# PIC32CZ4010CA90144 register map
Vendor: Microchip Technology; Series: PIC32CZCA90; File version: 0
CPU: CM7 r1p1, selectable endian, MPU, FPU, 3 interrupt priority bits
Registers are 32-bit, read-write, reset 0x0 unless marked. A register's access mark holds for its fields unless they carry their own. Offsets are from the block's base; [hi:lo] are bit positions; {n}, {i} and the like mark numbered series; 'fields as' and 'values as' point back to an identical list.

## PRM — Boot ROM Controller
Base 0x44080000; register names take the prefix PRM_
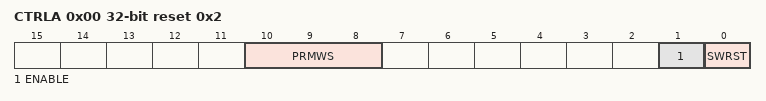
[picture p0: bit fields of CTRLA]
0x00 CTRLA reset 0x2 — CONTROL A REGISTER
  [10:8] PRMWS — ROM ACCESS TIME WAIT STATE
  [1] ENABLE — ENABLE BIT
  [0] SWRST — SOFTWARE RESET BIT

## PTC — Peripheral Touch Controller
Base 0x46828000; register names take the prefix PTC_

## RSTC — Reset Controller
Base 0x44030000; register names take the prefix RSTC_
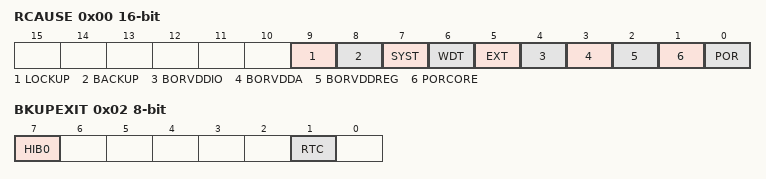
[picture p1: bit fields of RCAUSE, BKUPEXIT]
0x00 RCAUSE 16-bit ro — Reset Cause
  [9] LOCKUP — Lockup Reset
  [8] BACKUP — Backup Reset
  [7] SYST — System Reset Request
  [6] WDT — Watchdog Reset
  [5] EXT — External Reset
  [4] BORVDDIO — Brown Out VDDIO Detector Reset
  [3] BORVDDA — Brown Out VDDA Detector Reset
  [2] BORVDDREG — Brown Out VDDREG Detector Reset
  [1] PORCORE — Brown Out CORE Detector Reset
  [0] POR — Power On Reset
0x02 BKUPEXIT 8-bit ro — Backup Exit Source. Implemented only if RSTC_BACKUP_IMPLEMENTED=1
  [7] HIB0 — Hibernate
  [1] RTC — Real Timer Counter Interrupt
0x04 DBGCTRL — Debug Control
  [0] LCKUPDIS — Lockup Disable

## SysTick — System timer
Base 0xE000E010; register names take the prefix SysTick_
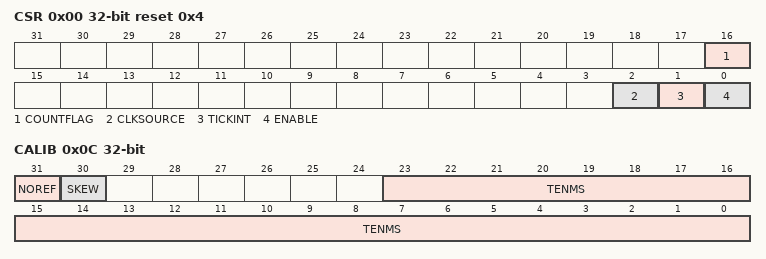
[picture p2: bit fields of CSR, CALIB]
0x00 CSR reset 0x4 — SysTick Control and Status Register
  [16] COUNTFLAG — Timer counted to 0 since last read of register
  [2] CLKSOURCE — Clock Source 0=external, 1=processor
    0=External clock; 1=Processor clock
  [1] TICKINT — SysTick Exception Request Enable
    0=Counting down to 0 does not assert the SysTick exception request; 1=Counting down to 0 asserts the SysTick exception request
  [0] ENABLE — SysTick Counter Enable
    0=Counter disabled; 1=Counter enabled
0x04 RVR — SysTick Reload Value Register
  [23:0] RELOAD — Value to load into the SysTick Current Value Register when the counter reaches 0
0x08 CVR — SysTick Current Value Register
  [23:0] CURRENT — Current value at the time the register is accessed
0x0C CALIB ro — SysTick Calibration Value Register
  [31] NOREF — No Separate Reference Clock
    0=The reference clock is provided; 1=The reference clock is not provided
  [30] SKEW — TENMS is rounded from non-integer ratio
    0=10ms calibration value is exact; 1=10ms calibration value is inexact, because of the clock frequency
  [23:0] TENMS — Reload value to use for 10ms timing

## TPI — Trace Port Interface Register
Base 0xE0040000; register names take the prefix TPI_
0x00 SSPSR ro — Supported Parallel Port Size Register
0x04 CSPSR — Current Parallel Port Size Register
0x10 ACPR — Asynchronous Clock Prescaler Register
  [12:0] PRESCALER
0xF0 SPPR — Selected Pin Protocol Register
  [1:0] TXMODE
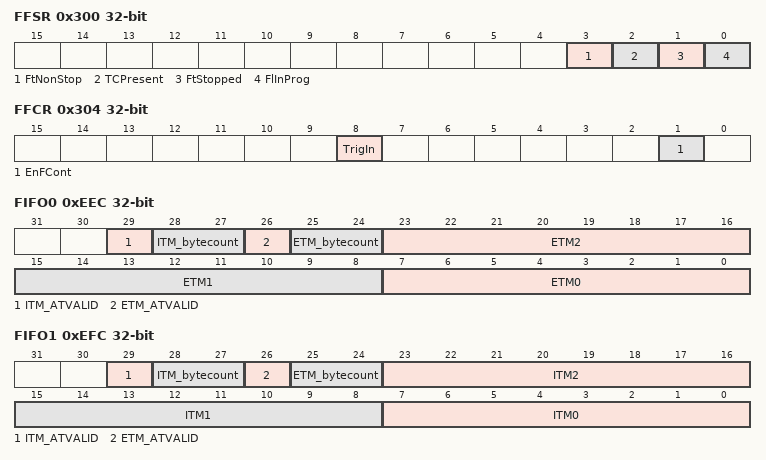
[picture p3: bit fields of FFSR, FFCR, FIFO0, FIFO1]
0x300 FFSR ro — Formatter and Flush Status Register
  [3] FtNonStop, [2] TCPresent, [1] FtStopped, [0] FlInProg
0x304 FFCR — Formatter and Flush Control Register
  [8] TrigIn, [1] EnFCont
0x308 FSCR ro — Formatter Synchronization Counter Register
0xEE8 TRIGGER ro
  [0] TRIGGER
0xEEC FIFO0 ro — Integration ETM Data
  [29] ITM_ATVALID, [28:27] ITM_bytecount, [26] ETM_ATVALID, [25:24] ETM_bytecount, [23:16] ETM2, [15:8] ETM1, [7:0] ETM0
0xEF0 ITATBCTR2 ro
  [0] ATREADY
0xEF8 ITATBCTR0 ro
  [0] ATREADY
0xEFC FIFO1 ro — Integration ITM Data
  [29] ITM_ATVALID, [28:27] ITM_bytecount, [26] ETM_ATVALID, [25:24] ETM_bytecount, [23:16] ITM2, [15:8] ITM1, [7:0] ITM0
0xF00 ITCTRL — Integration Mode Control
  [0] Mode
0xFA0 CLAIMSET — Claim tag set
0xFA4 CLAIMCLR — Claim tag clear
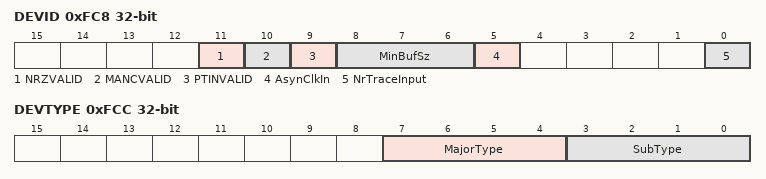
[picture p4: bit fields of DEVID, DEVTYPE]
0xFC8 DEVID ro — TPIU_DEVID
  [11] NRZVALID, [10] MANCVALID, [9] PTINVALID, [8:6] MinBufSz, [5] AsynClkIn, [0] NrTraceInput
0xFCC DEVTYPE ro — TPIU_DEVTYPE
  [7:4] MajorType, [3:0] SubType

## TRAM — TrustRAM
Base 0x44824000; register names take the prefix TRAM_
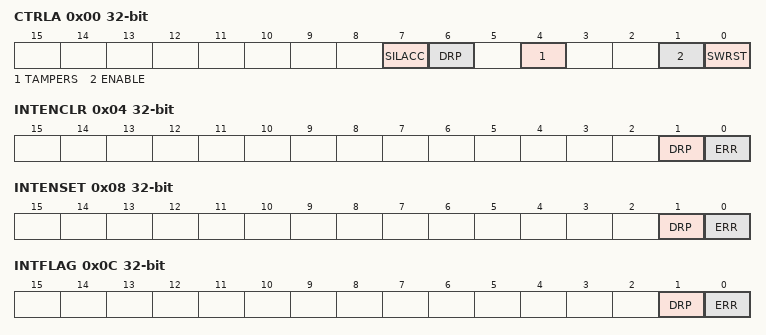
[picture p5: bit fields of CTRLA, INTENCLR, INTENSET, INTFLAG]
0x00 CTRLA — Control
  [7] SILACC — Silent Access
  [6] DRP — Data Remanence Prevention
  [4] TAMPERS — Tamper Erase
  [1] ENABLE
  [0] SWRST — Software Reset
0x04 INTENCLR — Interrupt Enable Clear
  [1] DRP — Data Remanence Prevention Ended Interrupt Enable
  [0] ERR — TrustRAM Readout Error Interrupt Enable
0x08 INTENSET — Interrupt Enable Set
  fields as INTENCLR
0x0C INTFLAG — Interrupt Flag Status and Clear
  [1] DRP — Data Remanence Prevention Ended
  [0] ERR — TrustRAM Readout Error
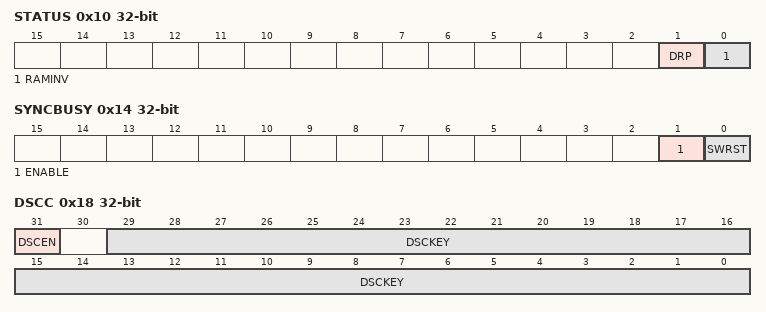
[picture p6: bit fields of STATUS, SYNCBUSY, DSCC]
0x10 STATUS ro
  [1] DRP — Data Remanence Prevention Ongoing
  [0] RAMINV — RAM Inversion Bit
0x14 SYNCBUSY ro — Synchronization Busy Status
  [1] ENABLE — Enable Busy
  [0] SWRST — Software Reset Busy
0x18 DSCC wo — Data Scramble Control
  [31] DSCEN — Data Scramble Enable
  [29:0] DSCKEY — Data Scramble Key
0x1C PERMW wo — Permutation Write
  [2:0] DATA — Permutation Scrambler Data Input
0x20 PERMR ro — Permutation Read
  [2:0] DATA — Permutation Scrambler Data Output
{0x1000+4i} RAM[{i}] (i=0..2047) — TrustRAM
  [31:0] DATA — Trust RAM Data

## TRNG — True Random Generator
Base 0x44870000; register names take the prefix TRNG_
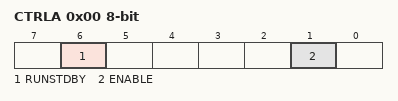
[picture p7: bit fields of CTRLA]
0x00 CTRLA 8-bit — Control A
  [6] RUNSTDBY — Run in Standby
  [1] ENABLE
0x04 EVCTRL 8-bit — Event Control
  [0] DATARDYEO — Data Ready Event Output
0x08 INTENCLR 8-bit — Interrupt Enable Clear
  [0] DATARDY — Data Ready Interrupt Enable
0x09 INTENSET 8-bit — Interrupt Enable Set
  [0] DATARDY — Data Ready Interrupt Enable
0x0A INTFLAG 8-bit — Interrupt Flag Status and Clear
  [0] DATARDY — Data Ready Interrupt Flag
0x20 DATA ro — Output Data

## WDT — Watchdog Timer
Base 0x44070000; register names take the prefix WDT_
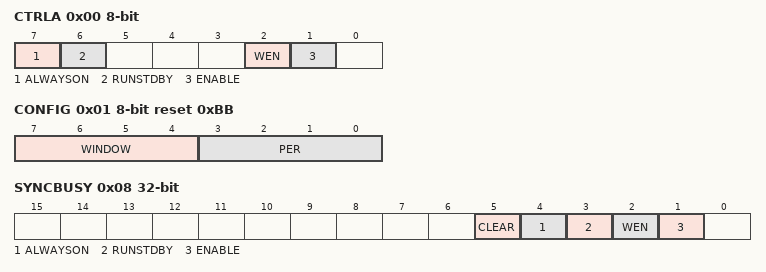
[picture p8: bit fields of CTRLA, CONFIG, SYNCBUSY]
0x00 CTRLA 8-bit — Control
  [7] ALWAYSON
  [6] RUNSTDBY — Run During Standby
  [2] WEN — Watchdog Timer Window Mode Enable
  [1] ENABLE
0x01 CONFIG 8-bit reset 0xBB — Configuration
  [7:4] WINDOW — Window Mode Time-Out Period
    0=CYC8 (8 clock cycles); 1=CYC16 (16 clock cycles); 2=CYC32 (32 clock cycles); 3=CYC64 (64 clock cycles); 4=CYC128 (128 clock cycles); 5=CYC256 (256 clock cycles); 6=CYC512 (512 clock cycles); 7=CYC1024 (1024 clock cycles); 8=CYC2048 (2048 clock cycles); 9=CYC4096 (4096 clock cycles); 10=CYC8192 (8192 clock cycles); 11=CYC16384 (16384 clock cycles)
  [3:0] PER — Time-Out Period
    values as WINDOW
0x02 EWCTRL 8-bit reset 0xB — Early Warning Interrupt Control
  [3:0] EWOFFSET — Early Warning Interrupt Time Offset
    values as CONFIG.WINDOW
0x04 INTENCLR 8-bit — Interrupt Enable Clear
  [0] EW — Early Warning Interrupt Enable
0x05 INTENSET 8-bit — Interrupt Enable Set
  [0] EW — Early Warning Interrupt Enable
0x06 INTFLAG 8-bit — Interrupt Flag Status and Clear
  [0] EW — Early Warning
0x08 SYNCBUSY ro — Synchronization Busy
  [5] CLEAR — Clear Synchronization Busy
  [4] ALWAYSON — Always-On Synchronization Busy
  [3] RUNSTDBY — Run During Standby Synchronization Busy
  [2] WEN — Window Enable Synchronization Busy
  [1] ENABLE — Enable Synchronization Busy
0x0C CLEAR 8-bit wo
  [7:0] CLEAR — Watchdog Clear
    165=KEY (Clear Key)
